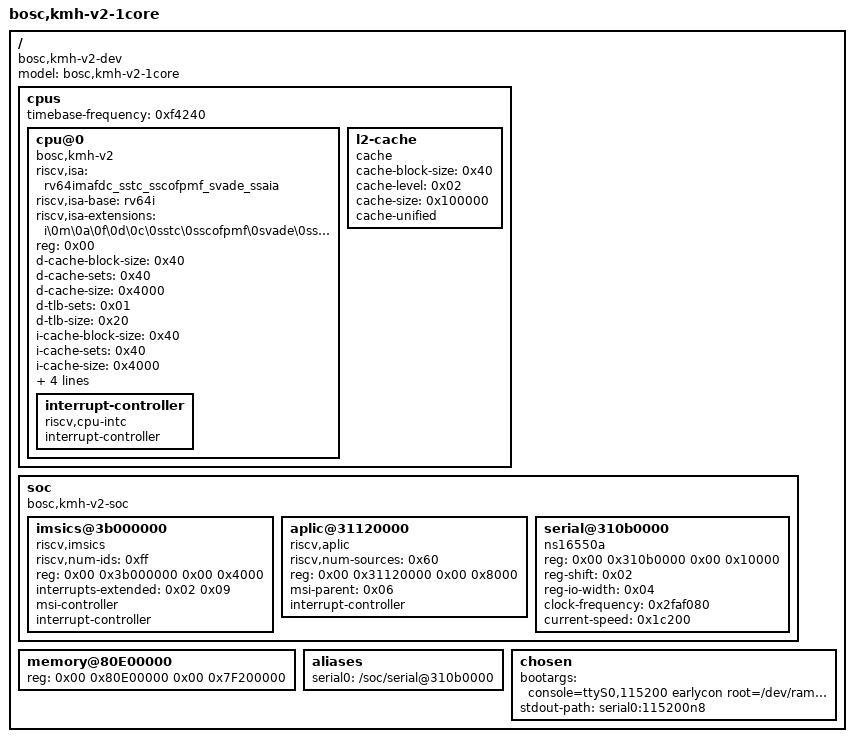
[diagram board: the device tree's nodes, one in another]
/dts-v1/;

/ {
	compatible = "bosc,kmh-v2-dev";
	#address-cells = <0x02>;
	#size-cells = <0x02>;
	model = "bosc,kmh-v2-1core";

	cpus {
		#address-cells = <0x01>;
		#size-cells = <0x00>;
		timebase-frequency = <0xf4240>;

		cpu@0 {
			compatible = "bosc,kmh-v2\0riscv";
			device_type = "cpu";
			riscv,isa = "rv64imafdc_sstc_sscofpmf_svade_ssaia";
			riscv,isa-base = "rv64i";
			riscv,isa-extensions = "i\0m\0a\0f\0d\0c\0sstc\0sscofpmf\0svade\0ssaia";
			reg = <0x00>;
			d-cache-block-size = <0x40>;
			d-cache-sets = <0x40>;
			d-cache-size = <0x4000>;
			d-tlb-sets = <0x01>;
			d-tlb-size = <0x20>;
			i-cache-block-size = <0x40>;
			i-cache-sets = <0x40>;
			i-cache-size = <0x4000>;
			i-tlb-sets = <0x01>;
			i-tlb-size = <0x20>;
			mmu-type = "riscv,sv39";
			next-level-cache = <0x01>;
			status = "okay";
			phandle = <0x0b>;

			interrupt-controller {
				compatible = "riscv,cpu-intc";
				interrupt-controller;
				#interrupt-cells = <0x01>;
				phandle = <0x02>;
			};
		};

		l2-cache {
			compatible = "cache";
			cache-block-size = <0x40>;
			cache-level = <0x02>;
			cache-size = <0x100000>;
			cache-unified;
			phandle = <0x01>;
		};
	};

	soc {
		#address-cells = <0x02>;
		#size-cells = <0x02>;
		compatible = "bosc,kmh-v2-soc\0simple-bus";
		ranges;

		imsics@3b000000 {
			riscv,num-ids = <0xff>;
			reg = <0x00 0x3b000000 0x00 0x4000>;
			interrupts-extended = <0x02 0x09>;
			msi-controller;
			interrupt-controller;
			#interrupt-cells = <0x00>;
			compatible = "riscv,imsics";
			phandle = <0x06>;
		};

		aplic@31120000 {
			riscv,num-sources = <0x60>;
			reg = <0x00 0x31120000 0x00 0x8000>;
			msi-parent = <0x06>;
			interrupt-controller;
			#interrupt-cells = <0x02>;
			compatible = "riscv,aplic";
			phandle = <0x07>;
		};

		serial@310b0000 {
			compatible = "ns16550a";
			reg = <0x00 0x310b0000 0x00 0x10000>;
			reg-shift = <0x02>;
			reg-io-width = <0x04>;
			clock-frequency = <0x2faf080>;
			current-speed = <0x1c200>;
			status = "okay";
		};
	};

	memory@80E00000 {
		device_type = "memory";
		reg = <0x00 0x80E00000 0x00 0x7F200000>;
	};

	aliases {
		serial0 = "/soc/serial@310b0000";
	};

	chosen {
		bootargs = "console=ttyS0,115200 earlycon root=/dev/ram rw";
		stdout-path = "serial0:115200n8";
	};
};
